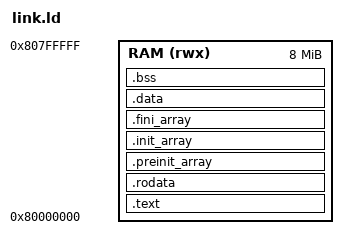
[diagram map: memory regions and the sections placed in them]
/*
 * Linker script for bare-metal RV32 programs using the QEMU 'virt' memory map.
 * Everything (code, data and stack) lives in RAM, the stack grows down from
 * the end of RAM and the heap grows up from _end. run.py maps the same RAM.
 */
OUTPUT_ARCH("riscv")
ENTRY(_start)

MEMORY
{
    RAM (rwx) : ORIGIN = 0x80000000, LENGTH = 8M
}

SECTIONS
{
    .text : {
        KEEP(*(.text.init))
        *(.text .text.*)
    } > RAM

    .rodata : ALIGN(8) {
        *(.rodata .rodata.*)
        *(.srodata .srodata.*)
    } > RAM

    .preinit_array : ALIGN(8) {
        PROVIDE_HIDDEN(__preinit_array_start = .);
        KEEP(*(.preinit_array))
        PROVIDE_HIDDEN(__preinit_array_end = .);
    } > RAM

    .init_array : ALIGN(8) {
        PROVIDE_HIDDEN(__init_array_start = .);
        KEEP(*(SORT(.init_array.*)))
        KEEP(*(.init_array))
        PROVIDE_HIDDEN(__init_array_end = .);
    } > RAM

    .fini_array : ALIGN(8) {
        PROVIDE_HIDDEN(__fini_array_start = .);
        KEEP(*(SORT(.fini_array.*)))
        KEEP(*(.fini_array))
        PROVIDE_HIDDEN(__fini_array_end = .);
    } > RAM

    .data : ALIGN(8) {
        *(.data .data.*)
        __global_pointer$ = . + 0x800;
        *(.sdata .sdata.*)
    } > RAM

    .bss (NOLOAD) : ALIGN(8) {
        __bss_start = .;
        *(.sbss .sbss.*)
        *(.bss .bss.*)
        *(COMMON)
        . = ALIGN(8);
        __bss_end = .;
    } > RAM

    . = ALIGN(16);
    _end = .;
    PROVIDE(end = .);

    __stack_top = ORIGIN(RAM) + LENGTH(RAM);
}
